# ESP32-S31 register map
Vendor: ESPRESSIF SYSTEMS (SHANGHAI) CO., LTD.; Series: ESP32 S-Series; File version: 1
CPU: RV32IMAFC r0p0, little endian, no MPU, FPU, 0 interrupt priority bits
Address unit: 32 bits
Registers are 32-bit, read-write, reset 0x0 unless marked. A register's access mark holds for its fields unless they carry their own. Offsets are from the block's base; [hi:lo] are bit positions; {n}, {i} and the like mark numbered series.

## HP_ALIVE_SYS — HP_ALIVE_SYS Peripheral
Base 0x20589000
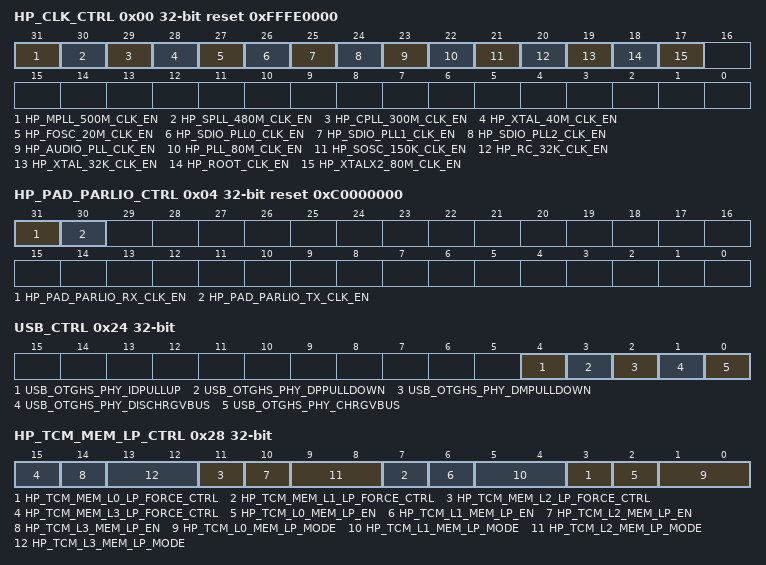
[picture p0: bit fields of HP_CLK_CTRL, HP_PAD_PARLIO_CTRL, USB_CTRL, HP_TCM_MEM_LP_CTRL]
0x00 HP_CLK_CTRL reset 0xFFFE0000 — HP Clock Control Register.
  [31] HP_MPLL_500M_CLK_EN — MPLL 500M Clock Enable.
  [30] HP_SPLL_480M_CLK_EN — SPLL 480M Clock Enable.
  [29] HP_CPLL_300M_CLK_EN — CPLL 300M Clock Enable.
  [28] HP_XTAL_40M_CLK_EN — XTAL 40M Clock Enalbe.
  [27] HP_FOSC_20M_CLK_EN — FOSC 20M Clock Enable.
  [26] HP_SDIO_PLL0_CLK_EN — reserved
  [25] HP_SDIO_PLL1_CLK_EN — reserved
  [24] HP_SDIO_PLL2_CLK_EN — reserved
  [23] HP_AUDIO_PLL_CLK_EN — AUDIO PLL Clock Enable.
  [22] HP_PLL_80M_CLK_EN — PLL 8M Clock Enable.
  [21] HP_SOSC_150K_CLK_EN — SOSC 150K Clock Enable.
  [20] HP_RC_32K_CLK_EN — RC 32K Clock Enable.
  [19] HP_XTAL_32K_CLK_EN — XTAL 32K Clock Enable.
  [18] HP_ROOT_CLK_EN — HP SoC Root Clock Enable.
  [17] HP_XTALX2_80M_CLK_EN — XTALx2 80M Clock Enalbe.
0x04 HP_PAD_PARLIO_CTRL reset 0xC0000000 — HP Clock Control Register.
  [31] HP_PAD_PARLIO_RX_CLK_EN — PARLIO RX Clock From Pad Enable.
  [30] HP_PAD_PARLIO_TX_CLK_EN — PARLIO TX Clock From Pad Enable.
0x08 HP_PAD_I2S0_CTRL reset 0x80000000 — HP Clock Control Register.
  [31] HP_PAD_I2S0_MCLK_EN — I2S0 MCLK Clock From Pad Enable.
0x0C HP_PAD_I2S1_CTRL reset 0x80000000 — HP Clock Control Register.
  [31] HP_PAD_I2S1_MCLK_EN — I2S1 MCLK Clock From Pad Enable.
{0x10+4i} HP_PAD_UART{i}_CTRL reset 0x80000000 (i=0..3) — HP Clock Control Register.
  [31] HP_PAD_UART{i}_SLP_CLK_EN — UART{i} SLP Clock From Pad Enable.
0x20 MODEM_CLK_AON reset 0x80000000 — need_des
  [31] SEL — Modem clk aon sel. 0: foscl 1:xtal
0x24 USB_CTRL — need_des
  [4] USB_OTGHS_PHY_IDPULLUP — phy idpullup
  [3] USB_OTGHS_PHY_DPPULLDOWN — phy dppulldown
  [2] USB_OTGHS_PHY_DMPULLDOWN — phy dmpulldown
  [1] USB_OTGHS_PHY_DISCHRGVBUS — phy dischrgvbus
  [0] USB_OTGHS_PHY_CHRGVBUS — phy chrgvbus
0x28 HP_TCM_MEM_LP_CTRL — configure rmemory power in lp system register
  [4n+3] HP_TCM_MEM_L{n}_LP_FORCE_CTRL (n=0..3) — Set this bit to force software control layer{n} hp_sram memory, disbale hardware control.
  [4n+2] HP_TCM_L{n}_MEM_LP_EN (n=0..3) — Set this bit to power down layer{n} hp_sram memory.
  [4n+1:4n] HP_TCM_L{n}_MEM_LP_MODE (n=0..3) — Configures layer{n} hp_sram memory low power mode in low power stage.\\ 0(default): deep sleep\\ 1: light sleep\\ 2: shut down\\ 3: disable low power stage\\
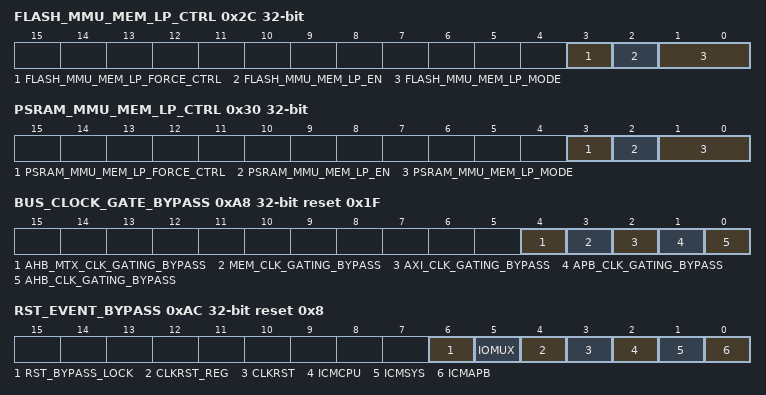
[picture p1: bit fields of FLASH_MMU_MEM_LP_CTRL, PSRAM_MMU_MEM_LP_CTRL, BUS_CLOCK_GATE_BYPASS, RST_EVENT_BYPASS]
0x2C FLASH_MMU_MEM_LP_CTRL — configure rmemory power in lp system register
  [3] FLASH_MMU_MEM_LP_FORCE_CTRL — Set this bit to force software control flash_mmu memory, disbale hardware control.
  [2] FLASH_MMU_MEM_LP_EN — Set this bit to power down flash_mmu memory.
  [1:0] FLASH_MMU_MEM_LP_MODE — Configures flash_mmu memory low power mode in low power stage.\\ 0: deep sleep\\ 1: light sleep\\ 2(default): shut down\\ 3: disable low power stage\\
0x30 PSRAM_MMU_MEM_LP_CTRL — configure rmemory power in lp system register
  [3] PSRAM_MMU_MEM_LP_FORCE_CTRL — Set this bit to force software control psram_mmu memory, disbale hardware control.
  [2] PSRAM_MMU_MEM_LP_EN — Set this bit to power down psram_mmu memory.
  [1:0] PSRAM_MMU_MEM_LP_MODE — Configures psram_mmu memory low power mode in low power stage.\\ 0: deep sleep\\ 1: light sleep\\ 2(default): shut down\\ 3: disable low power stage\\
0x34 SPRAM_MEM_AUX_CTRL reset 0x2070 — spram mem aux ctrl , control TOP/CNNT/MODEM power domain
0x38 SPRF_MEM_AUX_CTRL reset 0x2070 — sprf mem aux ctrl , control TOP/CNNT power domain
  [31:0] SPRF_MEM_AUX_CTRL — sprf mem aux ctrl , control TOP/CNNT/MODEM power domain
0x40 SDPRF_MEM_AUX_CTRL — need_des
  [31:0] SDPRF_MEM_AUX_CTRL — sdprf mem aux ctrl , control TOP/CNNT/MODEM power domain
0x44 CPU_SPROM_MEM_AUX_CTRL reset 0x70 — need_des
  [31:0] CPU_SPROM_MEM_AUX_CTRL — sprom mem aux ctrl , control CPU power domain
0x48 CPU_SPRF_MEM_AUX_CTRL reset 0x2070 — need_des
{0x7C+4i} INTR_HP2LP_CONF_{i} reset 0xFFFFFFFF (i=0..3) — intr hp2lp configuration register {i}
  [31:0] INTR_HP2LP_EN_{i} — reserved
0x8C INTR_HP2LP_CONF_4 reset 0xFF — intr hp2lp configuration register 4
  [7:0] INTR_HP2LP_EN_4 — reserved
{0x90+4i} INTR_HP2LP_STATUS_{i} ro (i=0..3) — intr hp2lp status register {i}
  [31:0] INTR_HP2LP_STATUS_{i} — reserved
0xA0 INTR_HP2LP_STATUS_4 ro — intr hp2lp status register 4
  [7:0] INTR_HP2LP_STATUS_4 — reserved
0xA4 CPU_SPRAM_MEM_AUX_CTRL reset 0x2070 — spram mem aux ctrl , control CPU power domain
0xA8 BUS_CLOCK_GATE_BYPASS reset 0x1F — bus clock gating bypass configuration register
  [4] AHB_MTX_CLK_GATING_BYPASS — Set 1 to bypass the clock gating for ahb mtx
  [3] MEM_CLK_GATING_BYPASS — Set 1 to bypass the clock gating for mem bus
  [2] AXI_CLK_GATING_BYPASS — Set 1 to bypass the clock gating for axi bus
  [1] APB_CLK_GATING_BYPASS — Set 1 to bypass the clock gating for apb bus
  [0] AHB_CLK_GATING_BYPASS — Set 1 to bypass the clock gating for ahb bus
0xAC RST_EVENT_BYPASS reset 0x8 — bus clock gating bypass configuration register
  [6] RST_BYPASS_LOCK — Set 1 to lock reset event bypass configuration
  [5] IOMUX — Set 1 to bypass none-power_on reset source
  [4] CLKRST_REG — Set 1 to bypass none-power_on reset source
  [3] CLKRST — Set 1 to bypass none-power_on reset source
  [2] ICMCPU — Set 1 to bypass none-power_on reset source
  [1] ICMSYS — Set 1 to bypass none-power_on reset source
  [0] ICMAPB — Set 1 to bypass none-power_on reset source
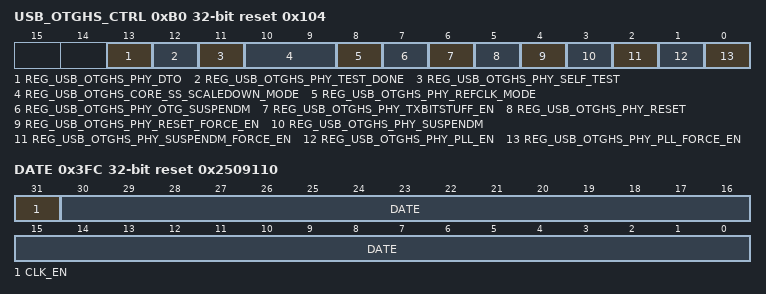
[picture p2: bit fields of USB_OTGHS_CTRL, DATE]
0xB0 USB_OTGHS_CTRL access per field reset 0x104 — usb_otghs Control configuration register
  [13] REG_USB_OTGHS_PHY_DTO ro — phy dto
  [12] REG_USB_OTGHS_PHY_TEST_DONE ro — phy test_bist
  [11] REG_USB_OTGHS_PHY_SELF_TEST rw — phy self_test
  [10:9] REG_USB_OTGHS_CORE_SS_SCALEDOWN_MODE rw — usb otghs core ss_scaledown_mode
  [8] REG_USB_OTGHS_PHY_REFCLK_MODE rw — phy refclk_mode
  [7] REG_USB_OTGHS_PHY_OTG_SUSPENDM rw — phy otg_suspendm
  [6] REG_USB_OTGHS_PHY_TXBITSTUFF_EN rw — phy txbitstuff_en
  [5] REG_USB_OTGHS_PHY_RESET rw — phy reset
  [4] REG_USB_OTGHS_PHY_RESET_FORCE_EN rw — Set this bit as 1 to force use reg_usb_otghs_phy_reset
  [3] REG_USB_OTGHS_PHY_SUSPENDM rw — phy suspendm
  [2] REG_USB_OTGHS_PHY_SUSPENDM_FORCE_EN rw — Set this bit as 1 to force use reg_usb_otghs_phy_suspendm
  [1] REG_USB_OTGHS_PHY_PLL_EN rw — pll_en for phy inf
  [0] REG_USB_OTGHS_PHY_PLL_FORCE_EN rw — Set this bit as 1 to force use reg_usb_otghs_phy_pll_en
0x3FC DATE reset 0x2509110 — need_des
  [31] CLK_EN — need_des
  [30:0] DATE — need_des
